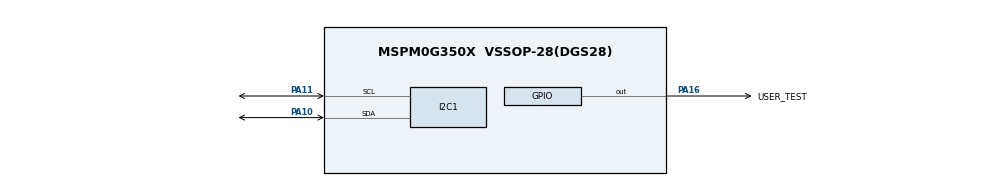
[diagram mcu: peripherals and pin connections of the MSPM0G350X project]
/**
 * @cliArgs --device "MSPM0G350X" --package "VSSOP-28(DGS28)" --part "Default" --product "mspm0_sdk@1.30.00.03"
 * @versions {"tool":"1.19.0+3426"}
 */

/**
 * Import the modules used in this configuration.
 */
const GPIO          = scripting.addModule("/ti/driverlib/GPIO", {}, false);
const GPIO1         = GPIO.addInstance();
const I2C           = scripting.addModule("/ti/driverlib/I2C", {}, false);
const I2C1          = I2C.addInstance();
const SYSCTL        = scripting.addModule("/ti/driverlib/SYSCTL");
const TIMER         = scripting.addModule("/ti/driverlib/TIMER", {}, false);
const TIMER1        = TIMER.addInstance();
const UART          = scripting.addModule("/ti/driverlib/UART", {}, false);
const UART1         = UART.addInstance();
const ProjectConfig = scripting.addModule("/ti/project_config/ProjectConfig");

/**
 * Write custom configuration values to the imported modules.
 */
const divider6       = system.clockTree["PLL_CLK2X_DIV"];
divider6.divideValue = 4;

const divider7       = system.clockTree["PLL_PDIV"];
divider7.divideValue = 2;

const divider9       = system.clockTree["UDIV"];
divider9.divideValue = 2;

const multiplier2         = system.clockTree["PLL_QDIV"];
multiplier2.multiplyValue = 10;

const mux3       = system.clockTree["EXCLKMUX"];
mux3.inputSelect = "EXCLKMUX_ULPCLK";

const mux8       = system.clockTree["HSCLKMUX"];
mux8.inputSelect = "HSCLKMUX_SYSPLL2X";

GPIO1.$name                         = "GPIO_LEDS";
GPIO1.port                          = "PORTA";
GPIO1.associatedPins[0].$name       = "USER_TEST";
GPIO1.associatedPins[0].pin.$assign = "PA16";

const Board = scripting.addModule("/ti/driverlib/Board", {}, false);

I2C1.$name                             = "I2C_EEPROM";
I2C1.basicEnableController             = true;
I2C1.basicEnableTarget                 = true;
I2C1.basicControllerStandardBusSpeed   = "Fast";
I2C1.basicTargetAddress                = 0x50;
I2C1.advAnalogGlitchFilter             = "5";
I2C1.advDigitalGlitchFilter            = "CLOCKS_1";
I2C1.advControllerRXFIFOTRIG           = "BYTES_8";
I2C1.advControllerTXFIFOTRIG           = "BYTES_7";
I2C1.advTargetTXFIFOTRIG               = "BYTES_1";
I2C1.intTarget                         = ["ARBITRATION_LOST","EVENT1_DMA_DONE","EVENT2_DMA_DONE","GENERAL_CALL","INTERRUPT_OVERFLOW ","RXFIFO_FULL","RXFIFO_OVERFLOW","RXFIFO_TRIGGER","RX_DONE","START","STOP","TXFIFO_EMPTY","TXFIFO_TRIGGER","TXFIFO_UNDERFLOW","TX_DONE"];
I2C1.peripheral.sdaPin.$assign         = "PA10";
I2C1.peripheral.sclPin.$assign         = "PA11";
I2C1.sdaPinConfig.hideOutputInversion  = scripting.forceWrite(false);
I2C1.sdaPinConfig.onlyInternalResistor = scripting.forceWrite(false);
I2C1.sdaPinConfig.passedPeripheralType = scripting.forceWrite("Digital");
I2C1.sdaPinConfig.$name                = "ti_driverlib_gpio_GPIOPinGeneric2";
I2C1.sclPinConfig.hideOutputInversion  = scripting.forceWrite(false);
I2C1.sclPinConfig.onlyInternalResistor = scripting.forceWrite(false);
I2C1.sclPinConfig.passedPeripheralType = scripting.forceWrite("Digital");
I2C1.sclPinConfig.$name                = "ti_driverlib_gpio_GPIOPinGeneric3";

SYSCTL.forceDefaultClkConfig = true;
SYSCTL.clockTreeEn           = true;

TIMER1.timerClkDiv      = 8;
TIMER1.timerClkPrescale = 256;
TIMER1.timerStartTimer  = true;
TIMER1.timerMode        = "PERIODIC";
TIMER1.$name            = "SWTIMER";
TIMER1.timerPeriod      = "1";

UART1.$name                            = "DEBUG_SCI";
UART1.targetBaudRate                   = 115200;
UART1.parity                           = "EVEN";
UART1.enableFIFO                       = true;
UART1.interruptPriority                = "2";
UART1.analogGlitchFilter               = "DL_UART_PULSE_WIDTH_25_NS";
UART1.digitalGlitchFilter              = 5;
UART1.enabledInterrupts                = ["DMA_DONE_RX"];
UART1.enabledDMARXTriggers             = "DL_UART_DMA_INTERRUPT_RX";
UART1.txPinConfig.direction            = scripting.forceWrite("OUTPUT");
UART1.txPinConfig.hideOutputInversion  = scripting.forceWrite(false);
UART1.txPinConfig.onlyInternalResistor = scripting.forceWrite(false);
UART1.txPinConfig.passedPeripheralType = scripting.forceWrite("Digital");
UART1.txPinConfig.$name                = "ti_driverlib_gpio_GPIOPinGeneric0";
UART1.rxPinConfig.hideOutputInversion  = scripting.forceWrite(false);
UART1.rxPinConfig.onlyInternalResistor = scripting.forceWrite(false);
UART1.rxPinConfig.passedPeripheralType = scripting.forceWrite("Digital");
UART1.rxPinConfig.$name                = "ti_driverlib_gpio_GPIOPinGeneric1";
UART1.DMA_CHANNEL_RX.$name             = "DMA_CH0";
UART1.DMA_CHANNEL_RX.destIncrement     = "INCREMENT";
UART1.DMA_CHANNEL_RX.transferMode      = "FULL_CH_REPEAT_SINGLE";
UART1.DMA_CHANNEL_RX.addressMode       = "f2b";

ProjectConfig.deviceSpin = "MSPM0G3507";

/**
 * Pinmux solution for unlocked pins/peripherals. This ensures that minor changes to the automatic solver in a future
 * version of the tool will not impact the pinmux you originally saw.  These lines can be completely deleted in order to
 * re-solve from scratch.
 */
Board.peripheral.$suggestSolution                = "DEBUGSS";
Board.peripheral.swclkPin.$suggestSolution       = "PA20";
Board.peripheral.swdioPin.$suggestSolution       = "PA19";
I2C1.peripheral.$suggestSolution                 = "I2C0";
TIMER1.peripheral.$suggestSolution               = "TIMA0";
UART1.peripheral.$suggestSolution                = "UART0";
UART1.peripheral.rxPin.$suggestSolution          = "PA1";
UART1.peripheral.txPin.$suggestSolution          = "PA0";
UART1.DMA_CHANNEL_RX.peripheral.$suggestSolution = "DMA_CH0";
